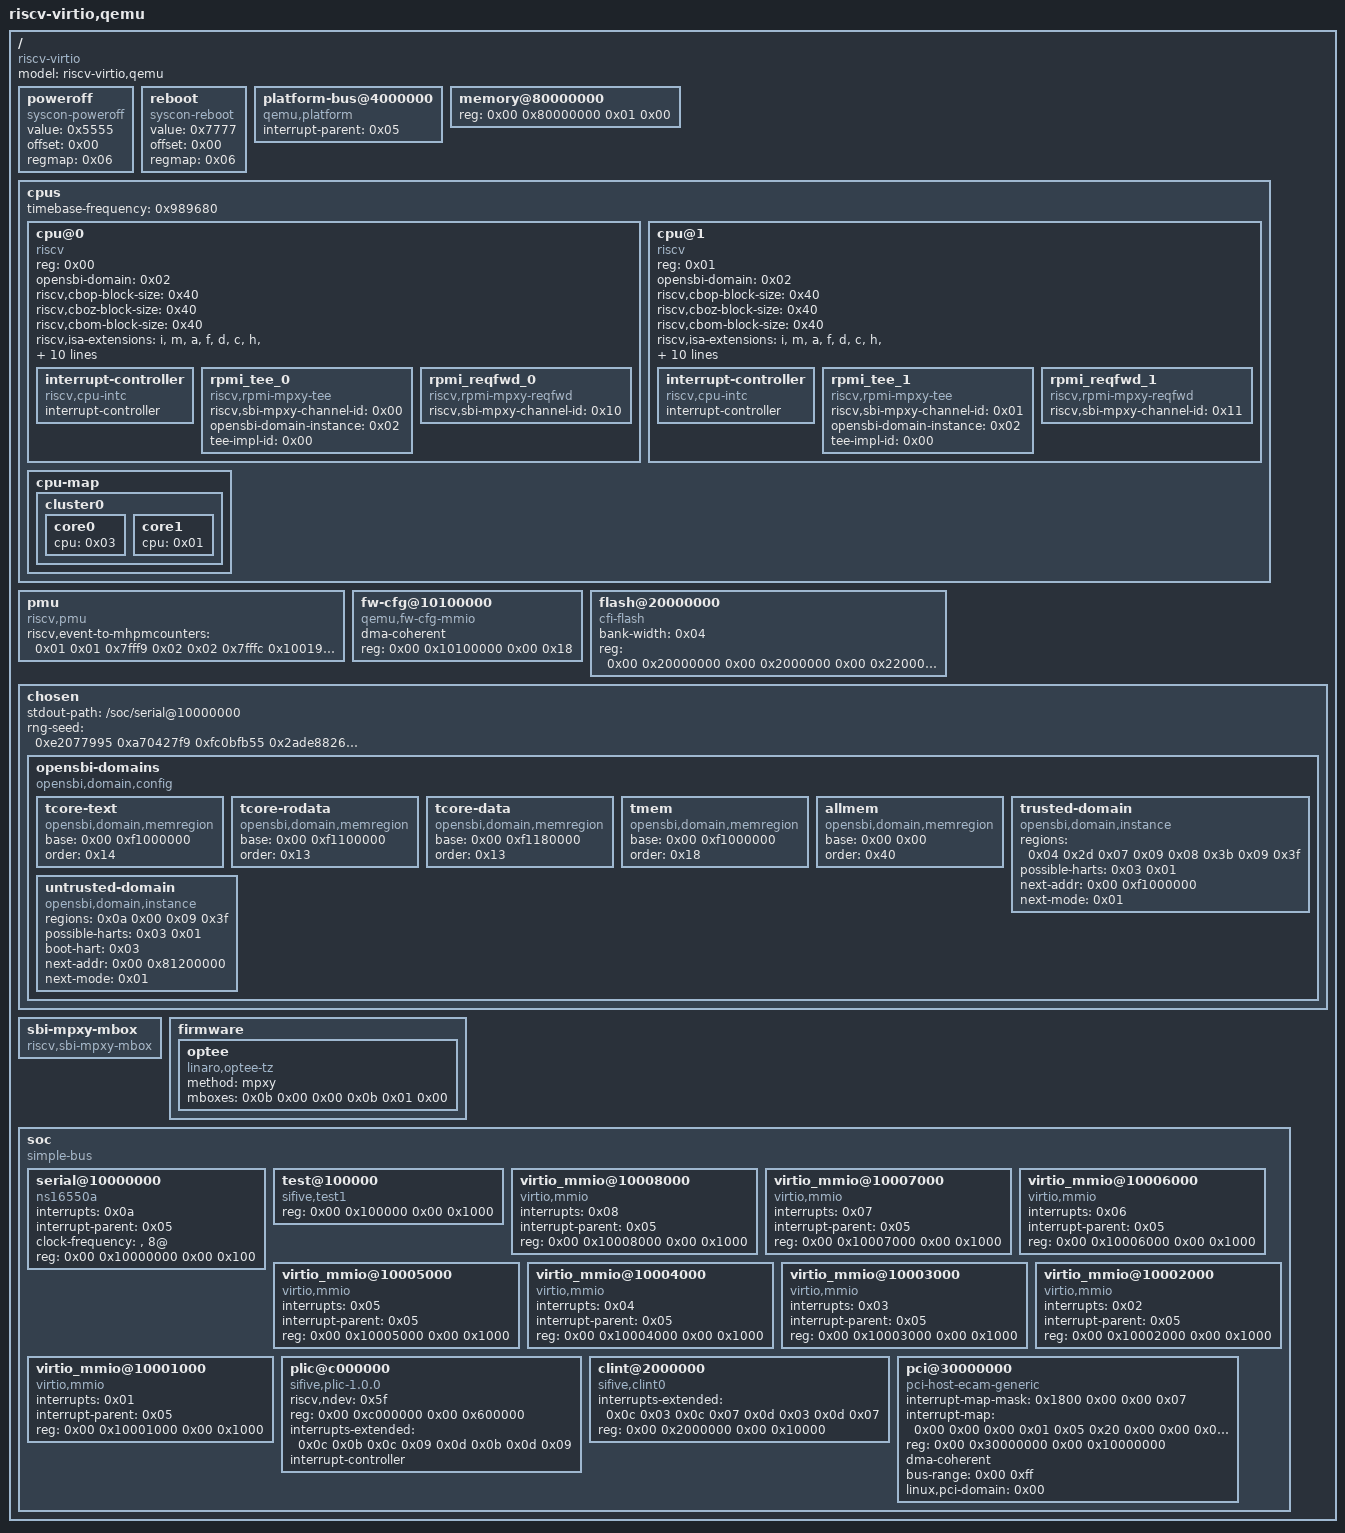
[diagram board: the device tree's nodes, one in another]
/dts-v1/;

/ {
	#address-cells = <0x02>;
	#size-cells = <0x02>;
	compatible = "riscv-virtio";
	model = "riscv-virtio,qemu";

	poweroff {
		value = <0x5555>;
		offset = <0x00>;
		regmap = <0x06>;
		compatible = "syscon-poweroff";
	};

	reboot {
		value = <0x7777>;
		offset = <0x00>;
		regmap = <0x06>;
		compatible = "syscon-reboot";
	};

	platform-bus@4000000 {
		interrupt-parent = <0x05>;
		ranges = <0x00 0x00 0x4000000 0x2000000>;
		#address-cells = <0x01>;
		#size-cells = <0x01>;
		compatible = "qemu,platform", "simple-bus";
	};

	memory@80000000 {
		device_type = "memory";
		reg = <0x00 0x80000000 0x01 0x00>;
	};

	cpus {
		#address-cells = <0x01>;
		#size-cells = <0x00>;
		timebase-frequency = <0x989680>;

		cpu@0 {
			phandle = <0x03>;
			device_type = "cpu";
			reg = <0x00>;
			status = "okay";
			compatible = "riscv";
			opensbi-domain = <0x02>;
			riscv,cbop-block-size = <0x40>;
			riscv,cboz-block-size = <0x40>;
			riscv,cbom-block-size = <0x40>;
			riscv,isa-extensions = "i", "m", "a", "f", "d", "c", "h", "zic64b", "zicbom", "zicbop", "zicboz", "ziccamoa", "ziccif", "zicclsm", "ziccrse", "zicntr", "zicsr", "zifencei", "zihintntl", "zihintpause", "zihpm", "za64rs", "zawrs", "zfa", "zca", "zcd", "zba", "zbb", "zbc", "zbs", "zkr", "ssccptr", "sscounterenw", "sstc", "sstvala", "sstvecd", "svadu";
			riscv,isa-base = "rv64i";
			riscv,isa = "rv64imafdch_zic64b_zicbom_zicbop_zicboz_ziccamoa_ziccif_zicclsm_ziccrse_zicntr_zicsr_zifencei_zihintntl_zihintpause_zihpm_za64rs_zawrs_zfa_zca_zcd_zba_zbb_zbc_zbs_zkr_ssccptr_sscounterenw_sstc_sstvala_sstvecd_svadu";
			mmu-type = "riscv,sv57";

			interrupt-controller {
				#interrupt-cells = <0x01>;
				interrupt-controller;
				compatible = "riscv,cpu-intc";
				phandle = <0x0c>;
			};

			rpmi_tee_0 {
				compatible = "riscv,rpmi-mpxy-tee";
				riscv,sbi-mpxy-channel-id = <0x00>;
				opensbi-domain-instance = <0x02>;
				tee-impl-id = <0x00>;
			};

			rpmi_reqfwd_0 {
				compatible = "riscv,rpmi-mpxy-reqfwd";
				riscv,sbi-mpxy-channel-id = <0x10>;
			};
		};

		cpu@1 {
			phandle = <0x01>;
			device_type = "cpu";
			reg = <0x01>;
			status = "okay";
			compatible = "riscv";
			opensbi-domain = <0x02>;
			riscv,cbop-block-size = <0x40>;
			riscv,cboz-block-size = <0x40>;
			riscv,cbom-block-size = <0x40>;
			riscv,isa-extensions = "i", "m", "a", "f", "d", "c", "h", "zic64b", "zicbom", "zicbop", "zicboz", "ziccamoa", "ziccif", "zicclsm", "ziccrse", "zicntr", "zicsr", "zifencei", "zihintntl", "zihintpause", "zihpm", "za64rs", "zawrs", "zfa", "zca", "zcd", "zba", "zbb", "zbc", "zbs", "zkr", "ssccptr", "sscounterenw", "sstc", "sstvala", "sstvecd", "svadu";
			riscv,isa-base = "rv64i";
			riscv,isa = "rv64imafdch_zic64b_zicbom_zicbop_zicboz_ziccamoa_ziccif_zicclsm_ziccrse_zicntr_zicsr_zifencei_zihintntl_zihintpause_zihpm_za64rs_zawrs_zfa_zca_zcd_zba_zbb_zbc_zbs_zkr_ssccptr_sscounterenw_sstc_sstvala_sstvecd_svadu";
			mmu-type = "riscv,sv57";

			interrupt-controller {
				#interrupt-cells = <0x01>;
				interrupt-controller;
				compatible = "riscv,cpu-intc";
				phandle = <0x0d>;
			};

			rpmi_tee_1 {
				compatible = "riscv,rpmi-mpxy-tee";
				riscv,sbi-mpxy-channel-id = <0x01>;
				opensbi-domain-instance = <0x02>;
				tee-impl-id = <0x00>;
			};

			rpmi_reqfwd_1 {
				compatible = "riscv,rpmi-mpxy-reqfwd";
				riscv,sbi-mpxy-channel-id = <0x11>;
			};
		};

		cpu-map {

			cluster0 {

				core0 {
					cpu = <0x03>;
				};

				core1 {
					cpu = <0x01>;
				};
			};
		};
	};

	pmu {
		riscv,event-to-mhpmcounters = <0x01 0x01 0x7fff9 0x02 0x02 0x7fffc 0x10019 0x10019 0x7fff8 0x1001b 0x1001b 0x7fff8 0x10021 0x10021 0x7fff8>;
		compatible = "riscv,pmu";
	};

	fw-cfg@10100000 {
		dma-coherent;
		reg = <0x00 0x10100000 0x00 0x18>;
		compatible = "qemu,fw-cfg-mmio";
	};

	flash@20000000 {
		bank-width = <0x04>;
		reg = <0x00 0x20000000 0x00 0x2000000 0x00 0x22000000 0x00 0x2000000>;
		compatible = "cfi-flash";
	};

	chosen {
		stdout-path = "/soc/serial@10000000";
		rng-seed = <0xe2077995 0xa70427f9 0xfc0bfb55 0x2ade8826 0x455a7930 0x1ebfece1 0xcf193c21 0x50a2aacc>;

		opensbi-domains {
			compatible = "opensbi,domain,config";

			tcore-text {
				compatible = "opensbi,domain,memregion";
				base = <0x00 0xf1000000>;
				order = <0x14>;
				phandle = <0x04>;
			};

			tcore-rodata {
				compatible = "opensbi,domain,memregion";
				base = <0x00 0xf1100000>;
				order = <0x13>;
				phandle = <0x07>;
			};

			tcore-data {
				compatible = "opensbi,domain,memregion";
				base = <0x00 0xf1180000>;
				order = <0x13>;
				phandle = <0x08>;
			};

			tmem {
				compatible = "opensbi,domain,memregion";
				base = <0x00 0xf1000000>;
				order = <0x18>;
				phandle = <0x0a>;
			};

			allmem {
				compatible = "opensbi,domain,memregion";
				base = <0x00 0x00>;
				order = <0x40>;
				phandle = <0x09>;
			};

			trusted-domain {
				compatible = "opensbi,domain,instance";
				regions = <0x04 0x2d 0x07 0x09 0x08 0x3b 0x09 0x3f>;
				possible-harts = <0x03 0x01>;
				next-addr = <0x00 0xf1000000>;
				next-mode = <0x01>;
				phandle = <0x02>;
			};

			untrusted-domain {
				compatible = "opensbi,domain,instance";
				regions = <0x0a 0x00 0x09 0x3f>;
				possible-harts = <0x03 0x01>;
				boot-hart = <0x03>;
				next-addr = <0x00 0x81200000>;
				next-mode = <0x01>;
			};
		};
	};

	sbi-mpxy-mbox {
		compatible = "riscv,sbi-mpxy-mbox";
		#mbox-cells = <0x02>;
		phandle = <0x0b>;
	};

	firmware {

		optee {
			compatible = "linaro,optee-tz";
			method = "mpxy";
			mboxes = <0x0b 0x00 0x00 0x0b 0x01 0x00>;
		};
	};

	soc {
		#address-cells = <0x02>;
		#size-cells = <0x02>;
		compatible = "simple-bus";
		ranges;

		serial@10000000 {
			interrupts = <0x0a>;
			interrupt-parent = <0x05>;
			clock-frequency = "", "8@";
			reg = <0x00 0x10000000 0x00 0x100>;
			compatible = "ns16550a";
		};

		test@100000 {
			phandle = <0x06>;
			reg = <0x00 0x100000 0x00 0x1000>;
			compatible = "sifive,test1", "sifive,test0", "syscon";
		};

		virtio_mmio@10008000 {
			interrupts = <0x08>;
			interrupt-parent = <0x05>;
			reg = <0x00 0x10008000 0x00 0x1000>;
			compatible = "virtio,mmio";
		};

		virtio_mmio@10007000 {
			interrupts = <0x07>;
			interrupt-parent = <0x05>;
			reg = <0x00 0x10007000 0x00 0x1000>;
			compatible = "virtio,mmio";
		};

		virtio_mmio@10006000 {
			interrupts = <0x06>;
			interrupt-parent = <0x05>;
			reg = <0x00 0x10006000 0x00 0x1000>;
			compatible = "virtio,mmio";
		};

		virtio_mmio@10005000 {
			interrupts = <0x05>;
			interrupt-parent = <0x05>;
			reg = <0x00 0x10005000 0x00 0x1000>;
			compatible = "virtio,mmio";
		};

		virtio_mmio@10004000 {
			interrupts = <0x04>;
			interrupt-parent = <0x05>;
			reg = <0x00 0x10004000 0x00 0x1000>;
			compatible = "virtio,mmio";
		};

		virtio_mmio@10003000 {
			interrupts = <0x03>;
			interrupt-parent = <0x05>;
			reg = <0x00 0x10003000 0x00 0x1000>;
			compatible = "virtio,mmio";
		};

		virtio_mmio@10002000 {
			interrupts = <0x02>;
			interrupt-parent = <0x05>;
			reg = <0x00 0x10002000 0x00 0x1000>;
			compatible = "virtio,mmio";
		};

		virtio_mmio@10001000 {
			interrupts = <0x01>;
			interrupt-parent = <0x05>;
			reg = <0x00 0x10001000 0x00 0x1000>;
			compatible = "virtio,mmio";
		};

		plic@c000000 {
			phandle = <0x05>;
			riscv,ndev = <0x5f>;
			reg = <0x00 0xc000000 0x00 0x600000>;
			interrupts-extended = <0x0c 0x0b 0x0c 0x09 0x0d 0x0b 0x0d 0x09>;
			interrupt-controller;
			compatible = "sifive,plic-1.0.0", "riscv,plic0";
			#address-cells = <0x00>;
			#interrupt-cells = <0x01>;
		};

		clint@2000000 {
			interrupts-extended = <0x0c 0x03 0x0c 0x07 0x0d 0x03 0x0d 0x07>;
			reg = <0x00 0x2000000 0x00 0x10000>;
			compatible = "sifive,clint0", "riscv,clint0";
		};

		pci@30000000 {
			interrupt-map-mask = <0x1800 0x00 0x00 0x07>;
			interrupt-map = <0x00 0x00 0x00 0x01 0x05 0x20 0x00 0x00 0x00 0x02 0x05 0x21 0x00 0x00 0x00 0x03 0x05 0x22 0x00 0x00 0x00 0x04 0x05 0x23 0x800 0x00 0x00 0x01 0x05 0x21 0x800 0x00 0x00 0x02 0x05 0x22 0x800 0x00 0x00 0x03 0x05 0x23 0x800 0x00 0x00 0x04 0x05 0x20 0x1000 0x00 0x00 0x01 0x05 0x22 0x1000 0x00 0x00 0x02 0x05 0x23 0x1000 0x00 0x00 0x03 0x05 0x20 0x1000 0x00 0x00 0x04 0x05 0x21 0x1800 0x00 0x00 0x01 0x05 0x23 0x1800 0x00 0x00 0x02 0x05 0x20 0x1800 0x00 0x00 0x03 0x05 0x21 0x1800 0x00 0x00 0x04 0x05 0x22>;
			ranges = <0x1000000 0x00 0x00 0x00 0x3000000 0x00 0x10000 0x2000000 0x00 0x40000000 0x00 0x40000000 0x00 0x40000000 0x3000000 0x04 0x00 0x04 0x00 0x04 0x00>;
			reg = <0x00 0x30000000 0x00 0x10000000>;
			dma-coherent;
			bus-range = <0x00 0xff>;
			linux,pci-domain = <0x00>;
			device_type = "pci";
			compatible = "pci-host-ecam-generic";
			#size-cells = <0x02>;
			#interrupt-cells = <0x01>;
			#address-cells = <0x03>;
		};
	};
};
